AUTOSAR XML (schema 00048)
package /HuaweiMDC/FunctionalSoftware/NavigationApplication/SwComponent
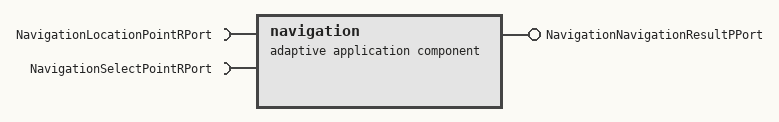
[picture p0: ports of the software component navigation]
  adaptive application sw component type navigation
    require port NavigationLocationPointRPort
    provide port NavigationNavigationResultPPort
    require port NavigationSelectPointRPort
